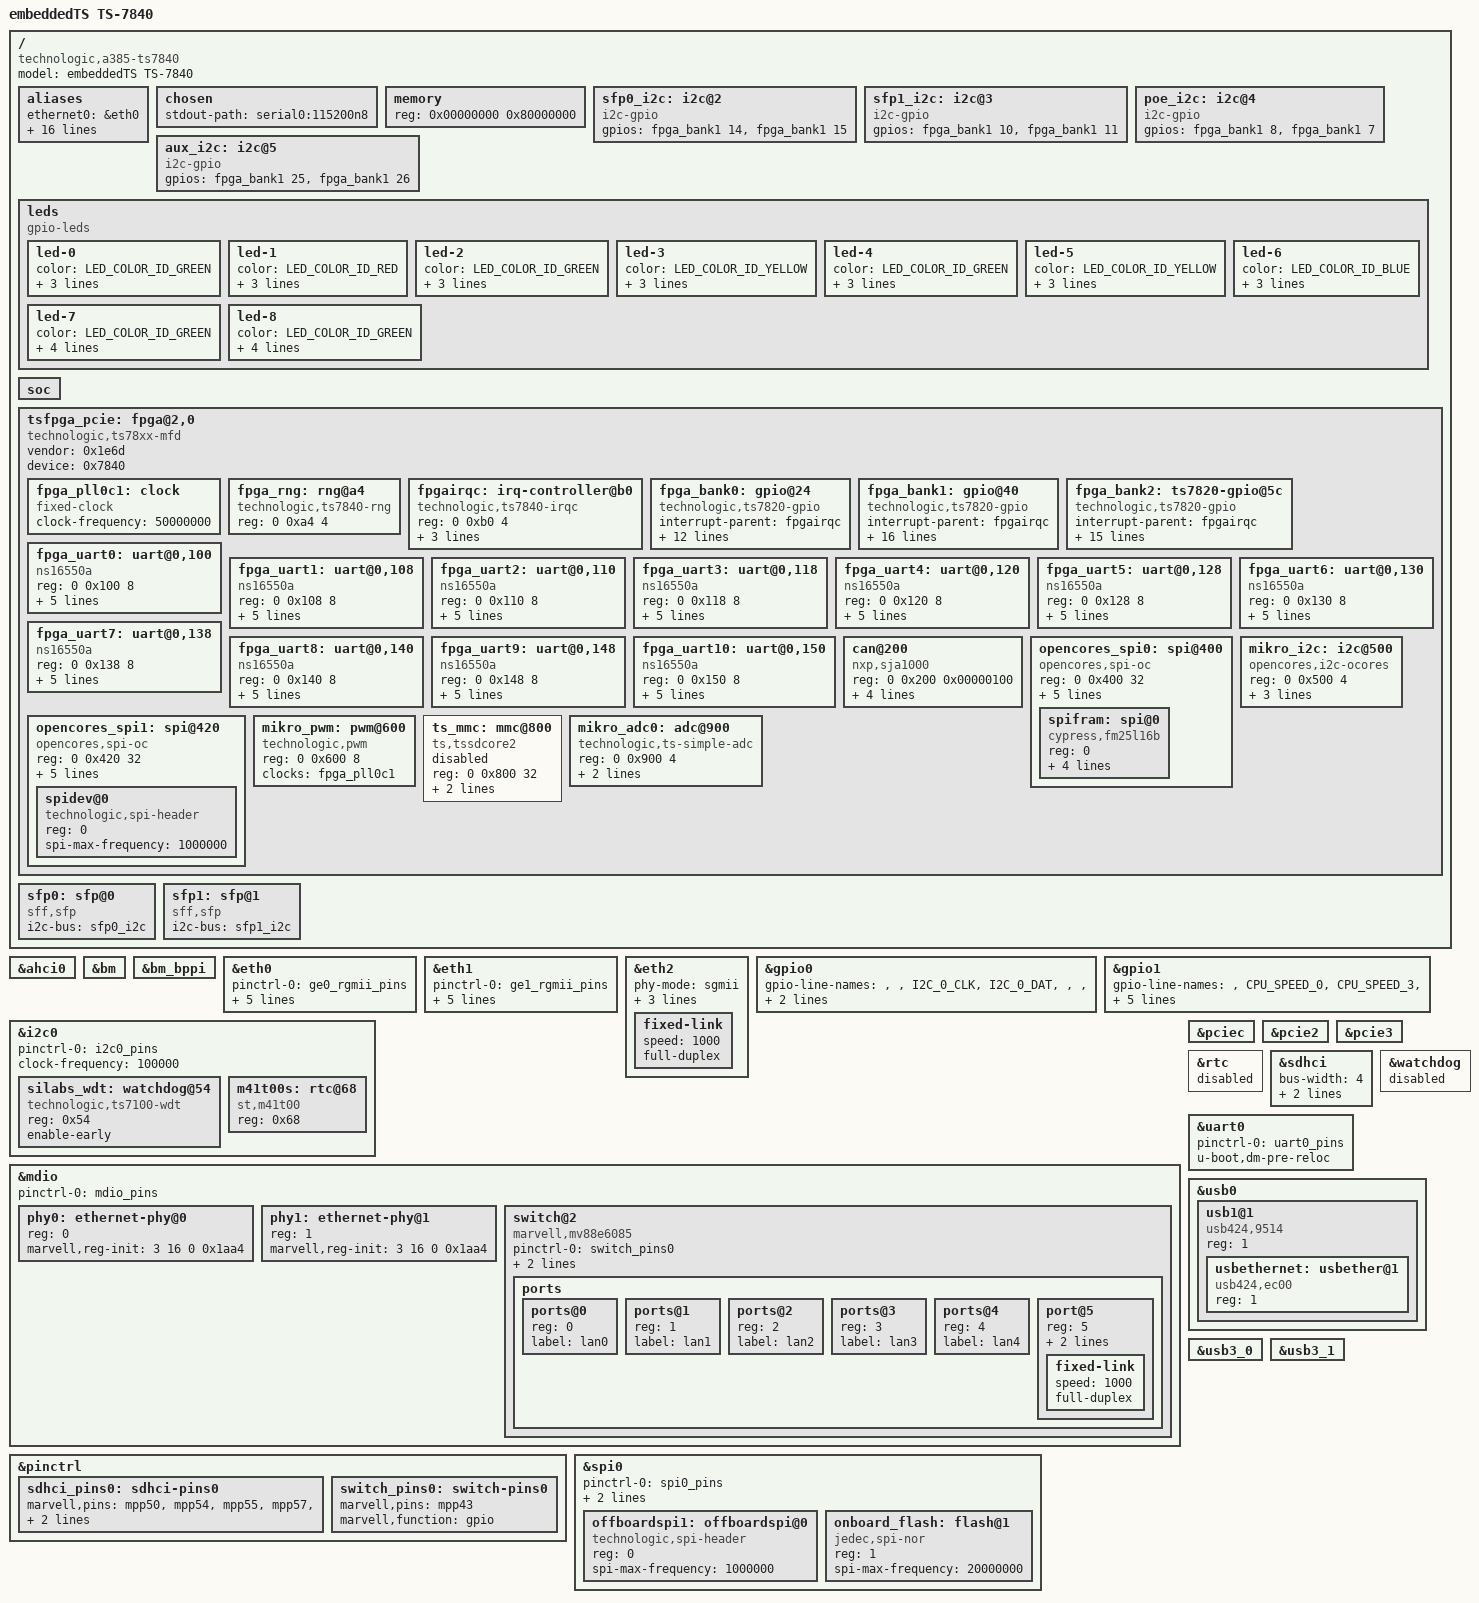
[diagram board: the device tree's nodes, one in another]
// SPDX-License-Identifier: (GPL-2.0+ OR X11)
/*
 * Device Tree file for embeddedTS TS-7840
 * Copyright (C) 2017-2022 Technologic Systems, Inc. dba embeddedTS
 */
/dts-v1/;
#include "armada-385.dtsi"

#include <dt-bindings/gpio/gpio.h>
#include <dt-bindings/leds/common.h>
#include <dt-bindings/interrupt-controller/irq.h>

/ {
	model = "embeddedTS TS-7840";
	compatible = "technologic,a385-ts7840", "marvell,armada385", "marvell,armada380";

	aliases {
		ethernet0 = &eth0;
		ethernet1 = &eth1;
		ethernet2 = &eth2;
		ethernet3 = &usbethernet;

		gpio2 = &fpga_bank0;
		gpio3 = &fpga_bank1;
		gpio4 = &fpga_bank2;

		spi0 = &spi0;
		spi3 = &opencores_spi0;
		spi4 = &opencores_spi1;

		i2c0 = &i2c0;
		i2c1 = &i2c1;
		i2c2 = &sfp0_i2c;
		i2c3 = &sfp1_i2c;
		i2c4 = &poe_i2c;
		i2c5 = &aux_i2c;
		i2c6 = &mikro_i2c;
	};

	chosen {
		stdout-path = "serial0:115200n8";
	};

	memory {
		device_type = "memory";
		reg = <0x00000000 0x80000000>; /* 2GB */
	};

	sfp0_i2c: i2c@2 {
		compatible = "i2c-gpio";
		gpios = <&fpga_bank1 14 (GPIO_ACTIVE_HIGH | GPIO_OPEN_DRAIN)>, /* sda */
			<&fpga_bank1 15 (GPIO_ACTIVE_HIGH | GPIO_OPEN_DRAIN)>; /* scl */
		#address-cells = <1>;
		#size-cells = <0>;
	};

	sfp1_i2c: i2c@3 {
		compatible = "i2c-gpio";
		gpios = <&fpga_bank1 10 (GPIO_ACTIVE_HIGH | GPIO_OPEN_DRAIN)>, /* sda */
			<&fpga_bank1 11 (GPIO_ACTIVE_HIGH | GPIO_OPEN_DRAIN)>; /* scl */
		#address-cells = <1>;
		#size-cells = <0>;
	};

	poe_i2c: i2c@4 {
		compatible = "i2c-gpio";
		gpios = <&fpga_bank1 8 (GPIO_ACTIVE_HIGH | GPIO_OPEN_DRAIN)>, /* sda */
			<&fpga_bank1 7 (GPIO_ACTIVE_HIGH | GPIO_OPEN_DRAIN)>; /* scl */
		#address-cells = <1>;
		#size-cells = <0>;
	};

	aux_i2c: i2c@5 {
		compatible = "i2c-gpio";
		gpios = <&fpga_bank1 25 (GPIO_ACTIVE_HIGH | GPIO_OPEN_DRAIN)>, /* sda */
			<&fpga_bank1 26 (GPIO_ACTIVE_HIGH | GPIO_OPEN_DRAIN)>; /* scl */
		#address-cells = <1>;
		#size-cells = <0>;
	};

	leds {
		compatible = "gpio-leds";

		led-0 {
			color = <LED_COLOR_ID_GREEN>;
			function = LED_FUNCTION_POWER;
			gpios = <&fpga_bank0 19 GPIO_ACTIVE_LOW>;
			default-state = "on";
		};

		led-1 {
			color = <LED_COLOR_ID_RED>;
			function = LED_FUNCTION_STATUS;
			gpios = <&fpga_bank0 20 GPIO_ACTIVE_LOW>;
			default-state = "off";
		};

		led-2 {
			color = <LED_COLOR_ID_GREEN>;
			function = LED_FUNCTION_INDICATOR;
			gpios = <&fpga_bank0 21 GPIO_ACTIVE_LOW>;
			default-state = "off";
		};

		led-3 {
			color = <LED_COLOR_ID_YELLOW>;
			function = LED_FUNCTION_INDICATOR;
			gpios = <&fpga_bank0 22 GPIO_ACTIVE_LOW>;
			default-state = "off";
		};

		led-4 {
			color = <LED_COLOR_ID_GREEN>;
			function = LED_FUNCTION_INDICATOR;
			gpios = <&fpga_bank0 23 GPIO_ACTIVE_LOW>;
			default-state = "off";
		};

		led-5 {
			color = <LED_COLOR_ID_YELLOW>;
			function = LED_FUNCTION_INDICATOR;
			gpios = <&fpga_bank0 24 GPIO_ACTIVE_LOW>;
			default-state = "off";
		};

		led-6 {
			color = <LED_COLOR_ID_BLUE>;
			function = LED_FUNCTION_INDICATOR;
			gpios = <&fpga_bank0 25 GPIO_ACTIVE_HIGH>;
			default-state = "off";
		};

		led-7 {
			color = <LED_COLOR_ID_GREEN>;
			gpios = <&fpga_bank0 26 GPIO_ACTIVE_LOW>;
			function = LED_FUNCTION_INDICATOR;
			linux,default-trigger = "f1072004.mdio-mii:01:1Gbps";
		};

		led-8 {
			color = <LED_COLOR_ID_GREEN>;
			gpios = <&fpga_bank2 20 GPIO_ACTIVE_LOW>;
			function = LED_FUNCTION_INDICATOR;
			linux,default-trigger = "f1072004.mdio-mii:00:1Gbps";
		};
	};

	soc {
		ranges = <MBUS_ID(0xf0, 0x01) 0 0xf1000000 0x100000
			  MBUS_ID(0x01, 0x1d) 0 0xfff00000 0x100000
			  MBUS_ID(0x09, 0x19) 0 0xf1100000 0x10000
			  MBUS_ID(0x09, 0x15) 0 0xf1110000 0x10000
			  MBUS_ID(0x0c, 0x04) 0 0xf1200000 0x100000>;
	};

	tsfpga_pcie: fpga@2,0 {
		compatible = "technologic,ts78xx-mfd";
		#address-cells = <2>;
		#size-cells = <1>;

		vendor = <0x1e6d>;
		device = <0x7840>;

		/* <ranges> is set in the driver at runtime */

		fpga_pll0c1: clock {
			compatible = "fixed-clock";
			#clock-cells = <0>;
			clock-frequency = <50000000>;
		};

		fpga_rng: rng@a4 {
			compatible = "technologic,ts7840-rng";
			reg = <0 0xa4 4>;
		};

		fpgairqc: irq-controller@b0 {
			compatible = "technologic,ts7840-irqc";
			reg = <0 0xb0 4>;
			interrupt-controller;
			#interrupt-cells = <2>;
			interrupt-parent = <&gpio1>;
			interrupts = <3 IRQ_TYPE_LEVEL_HIGH>;
		};

		fpga_bank0: gpio@24 {
			compatible = "technologic,ts7820-gpio";

			interrupt-parent = <&fpgairqc>;
			interrupts = <16 IRQ_TYPE_LEVEL_HIGH>;

			interrupt-controller;
			#interrupt-cells = <2>;

			gpio-controller;
			#gpio-cells = <2>;
			reg = <0 0x24 0x1c>;

			gpio-line-names = "", "", "", "", "", "", "", "", "",
				"", "", "", "", "", "", "", "power_fail_3v_pad",
				"detect_9478_pad", "", "magjack_1_led_padn",
				"blu_led_padn", "right_grn_led_padn",
				"right_red_led_padn", "middle_grn_led_padn",
				"middle_yel_led_padn", "left_grn_led_padn",
				"left_yel_led_padn", "bt_en_pad", "wifi_en_pad",
				"prog_silab_clk_padn", "prog_silab_data_pad",
				"cpu_push_sw_padn";
		};

		fpga_bank1: gpio@40 {
			compatible = "technologic,ts7820-gpio";

			interrupt-parent = <&fpgairqc>;
			interrupts = <17 IRQ_TYPE_LEVEL_HIGH>;

			interrupt-controller;
			#interrupt-cells = <2>;

			gpio-controller;
			#gpio-cells = <2>;
			reg = <0 0x40 0x1c>;

			gpio-line-names = "DIG_IO_1", "DIG_IO_2", "DIG_IO_3",
				"en_hs_sw_pad", "mikro_pwm_pad",
				"dio_fault_3v_padn", "en_poe_padn",
				"i2c_poe_clk_pad", "i2c_poe_dat",
				"spi_0_fpga_cs3_pad", "cage1_sda_pad",
				"cage1_scl_pad", "", "", "cage2_sda_pad",
				"cage2_scl_pad", "en_nimbel_4v_pad",
				"en_nimbel_3v3_pad", "en_emmc_3v3_pad",
				"en_modem_5v_pad", "en_usb_5v_pad",
				"disable_nim_usb_pad", "mini_pcie_reset_padn",
				"ssd_present_padn", "en_xbee_usb_padn",
				"aux_i2c_dat_pad", "aux_i2c_clk_pad", "", "",
				"", "", "";
		};

		fpga_bank2: ts7820-gpio@5c {
			compatible = "technologic,ts7820-gpio";

			interrupt-parent = <&fpgairqc>;
			interrupts = <18 IRQ_TYPE_LEVEL_HIGH>;

			interrupt-controller;
			#interrupt-cells = <2>;

			gpio-controller;
			#gpio-cells = <2>;
			reg = <0 0x5c 0x1c>;

			gpio-line-names = "ird_network_rdy_pad",
				"ird_modem_on_pad", "eth_100_act_padn",
				"eth_100_speed_padn", "ssd_act_padn",
				"mini_sr_latch_pad", "", "", "", "",
				"mikro_int_pad", "mikro_reset_padn",
				"mikro_an_3v_pad", "mikro_i2c_clk_pad",
				"mikro_i2c_dat_pad", "alt_mikro_pwm_pad",
				"mikro_an_pwm_pad", "comp_pad", "mikro_180_pad",
				"en_mini_5v_pad", "magjack_0_led_padn",
				"hd10_2_pad", "hd10_4_pad", "hd10_5_pad",
				"hd10_6_pad", "hd10_8_pad", "jp1_padn",
				"jp2_padn", "", "", "", "";
		};

		/* COM1 RS-232 */
		fpga_uart0: uart@0,100 {
			compatible = "ns16550a";
			reg = <0 0x100 8>;
			interrupt-parent = <&fpgairqc>;
			interrupts = <0 IRQ_TYPE_LEVEL_HIGH>;
			clock-frequency = <1843200>;
			reg-io-width = <1>;
			fifo-size = <64>;
		};

		/* COM2 RS-232 */
		fpga_uart1: uart@0,108 {
			compatible = "ns16550a";
			reg = <0 0x108 8>;
			interrupt-parent = <&fpgairqc>;
			interrupts = <1 IRQ_TYPE_LEVEL_HIGH>;
			clock-frequency = <1843200>;
			reg-io-width = <1>;
			fifo-size = <64>;
		};

		/* GPS */
		fpga_uart2: uart@0,110 {
			compatible = "ns16550a";
			reg = <0 0x110 8>;
			interrupt-parent = <&fpgairqc>;
			interrupts = <2 IRQ_TYPE_LEVEL_HIGH>;
			clock-frequency = <1843200>;
			reg-io-width = <1>;
			fifo-size = <64>;
		};

		/* Nimbelink */
		fpga_uart3: uart@0,118 {
			compatible = "ns16550a";
			reg = <0 0x118 8>;
			interrupt-parent = <&fpgairqc>;
			interrupts = <3 IRQ_TYPE_LEVEL_HIGH>;
			clock-frequency = <1843200>;
			reg-io-width = <1>;
			fifo-size = <64>;
		};

		/* Iridium Modem */
		fpga_uart4: uart@0,120 {
			compatible = "ns16550a";
			reg = <0 0x120 8>;
			interrupt-parent = <&fpgairqc>;
			interrupts = <4 IRQ_TYPE_LEVEL_HIGH>;
			clock-frequency = <1843200>;
			reg-io-width = <1>;
			fifo-size = <64>;
		};

		/* DSL Modem */
		fpga_uart5: uart@0,128 {
			compatible = "ns16550a";
			reg = <0 0x128 8>;
			interrupt-parent = <&fpgairqc>;
			interrupts = <5 IRQ_TYPE_LEVEL_HIGH>;
			clock-frequency = <1843200>;
			reg-io-width = <1>;
			fifo-size = <64>;
		};

		/* Mikrobus UART */
		fpga_uart6: uart@0,130 {
			compatible = "ns16550a";
			reg = <0 0x130 8>;
			interrupt-parent = <&fpgairqc>;
			interrupts = <6 IRQ_TYPE_LEVEL_HIGH>;
			clock-frequency = <1843200>;
			reg-io-width = <1>;
			fifo-size = <64>;
		};

		/* RS-485 port */
		fpga_uart7: uart@0,138 {
			compatible = "ns16550a";
			reg = <0 0x138 8>;
			interrupt-parent = <&fpgairqc>;
			interrupts = <7 IRQ_TYPE_LEVEL_HIGH>;
			clock-frequency = <1843200>;
			reg-io-width = <1>;
			fifo-size = <64>;
		};

		/* XBEE */
		fpga_uart8: uart@0,140 {
			compatible = "ns16550a";
			reg = <0 0x140 8>;
			interrupt-parent = <&fpgairqc>;
			interrupts = <8 IRQ_TYPE_LEVEL_HIGH>;
			clock-frequency = <1843200>;
			reg-io-width = <1>;
			fifo-size = <64>;
		};

		/* Spare */
		fpga_uart9: uart@0,148 {
			compatible = "ns16550a";
			reg = <0 0x148 8>;
			interrupt-parent = <&fpgairqc>;
			interrupts = <19 IRQ_TYPE_LEVEL_HIGH>;
			clock-frequency = <1843200>;
			reg-io-width = <1>;
			fifo-size = <64>;
		};

		/* Spare */
		fpga_uart10: uart@0,150 {
			compatible = "ns16550a";
			reg = <0 0x150 8>;
			interrupt-parent = <&fpgairqc>;
			interrupts = <20 IRQ_TYPE_LEVEL_HIGH>;
			clock-frequency = <1843200>;
			reg-io-width = <1>;
			fifo-size = <64>;
		};

		can@200 {
			compatible = "nxp,sja1000";
			reg = <0 0x200 0x00000100>;
			interrupt-parent = <&fpgairqc>;
			interrupts = <10 IRQ_TYPE_LEVEL_HIGH>;
			reg-io-width = <1>;
			nxp,external-clock-frequency = <16000000>;
		};

		opencores_spi0: spi@400 {
			compatible = "opencores,spi-oc";
			reg = <0 0x400 32>;
			interrupt-parent = <&fpgairqc>;
			interrupts = <11 IRQ_TYPE_LEVEL_HIGH>;
			clocks = <&fpga_pll0c1>;
			clock-names ="spi-oc-clk";
			opencores-spi,idx = <0>;
			opencores-spi,num-chipselects = <1>;

			#address-cells = <1>;
			#size-cells = <0>;

			spifram: spi@0 {
				compatible = "cypress,fm25l16b", "atmel,at25";
				reg = <0>;
				spi-max-frequency = <19800000>;
				size = <0x800>;
				address-width = <16>;
				pagesize = <64>;
			};
		};

		opencores_spi1: spi@420 {
			compatible = "opencores,spi-oc";
			reg = <0 0x420 32>;
			interrupt-parent = <&fpgairqc>;
			interrupts = <12 IRQ_TYPE_LEVEL_HIGH>;
			clocks = <&fpga_pll0c1>;
			clock-names ="spi-oc-clk";
			opencores-spi,idx = <0>;
			opencores-spi,num-chipselects = <1>;

			#address-cells = <1>;
			#size-cells = <0>;

			spidev@0 {
				compatible = "technologic,spi-header";
				reg = <0>;
				spi-max-frequency = <1000000>;
			};
		};

		mikro_i2c: i2c@500 {
			compatible = "opencores,i2c-ocores";
			reg = <0 0x500 4>;
			interrupt-parent = <&fpgairqc>;
			interrupts = <13 IRQ_TYPE_LEVEL_HIGH>;
			clocks = <&fpga_pll0c1>;
			clock-names = "i2c-oc-clk";
		};

		mikro_pwm: pwm@600 {
			compatible = "technologic,pwm";
			reg = <0 0x600 8>;
			clocks = <&fpga_pll0c1>;
			clock-names = "pwm-input-clk";
		};

		ts_mmc: mmc@800 {
			compatible = "ts,tssdcore2";
			reg = <0 0x800 32>;
			//interrupt-parent = <&fpgairqc>;
			//interrupts = <14 IRQ_TYPE_LEVEL_HIGH>;
			busy-gpios = <&fpga_bank0 15 GPIO_ACTIVE_HIGH>;
			debug-gpios = <&fpga_bank1 12 GPIO_ACTIVE_HIGH>;
			status = "disabled";
		};

		mikro_adc0: adc@900 {
			compatible = "technologic,ts-simple-adc";
			reg = <0 0x900 4>;
			interrupt-parent = <&fpgairqc>;
			interrupts = <21 IRQ_TYPE_LEVEL_HIGH>;
		};
	};

	sfp0: sfp@0 {
		compatible = "sff,sfp";
		i2c-bus = <&sfp0_i2c>;
	};

	sfp1: sfp@1 {
		compatible = "sff,sfp";
		i2c-bus = <&sfp1_i2c>;
	};
};

&ahci0 {
	status = "okay";
};

&bm {
	status = "okay";
};

&bm_bppi {
	status = "okay";
};

/* magjack/sfp port 0 */
&eth0 {
	pinctrl-names = "default";
	pinctrl-0 = <&ge0_rgmii_pins>;
	status = "okay";
	phy = <&phy0>;
	phy-mode = "rgmii-id";
	buffer-manager = <&bm>;
	/*sfp = <&sfp0>;*/
	bm,pool-long = <0>;
	bm,pool-short = <1>;
};

/* magjack/sfgp port 1 */
&eth1 {
	pinctrl-names = "default";
	pinctrl-0 = <&ge1_rgmii_pins>;
	status = "okay";
	phy = <&phy1>;
	phy-mode = "rgmii-id";
	/*sfp = <&sfp1>;*/
	bm,pool-long = <2>;
	bm,pool-short = <1>;
	buffer-manager = <&bm>;
};

/* sgmii port to eth switch */
&eth2 {
	status = "okay";
	phy-mode = "sgmii";
	bm,pool-long = <3>;
	bm,pool-short = <1>;
	buffer-manager = <&bm>;

	fixed-link {
		speed = <1000>;
		full-duplex;
	};
};

&gpio0 {
	gpio-line-names = "", "", "I2C_0_CLK", "I2C_0_DAT", "", "", "", "", "",
		"", "", "", "", "", "", "", "", "", "WIFI_IRQ_N", "FPGA_RESET",
		"", "", "", "", "", "", "", "", "", "", "", "";
};

&gpio1 {
	gpio-line-names = "", "CPU_SPEED_0", "CPU_SPEED_3", "CPU_SPEED_4",
		"CPU_TYPE_0", "", "", "", "", "", "GPS_PPS", "ETH_SW_INT#",
		"CPU_TYPE_1", "", "", "", "", "FPGA_FLASH_SELECT", "EMMC_CMD",
		"SPREAD_SPECTRUM#", "", "DETECT_9478", "", "", "", "", "", "",
		"", "", "", "";
};

&i2c0 {
	pinctrl-names = "default";
	pinctrl-0 = <&i2c0_pins>;
	clock-frequency = <100000>;
	status = "okay";

	silabs_wdt: watchdog@54 {
		compatible = "technologic,ts7100-wdt";
		reg = <0x54>;
		enable-early;
	};

	m41t00s: rtc@68 {
		compatible = "st,m41t00";
		reg = <0x68>;
	};
};

&mdio {
	pinctrl-names = "default";
	pinctrl-0 = <&mdio_pins>;

	phy0: ethernet-phy@0 {
		reg = <0>;
		/* Configure LED[0] to blink for activity */
		marvell,reg-init = <3 16 0 0x1aa4>;
	};

	phy1: ethernet-phy@1 {
		reg = <1>;
		/* Configure LED[0] to blink for activity */
		marvell,reg-init = <3 16 0 0x1aa4>;
	};

	switch@2 {
		compatible = "marvell,mv88e6085";

		pinctrl-names = "default";
		pinctrl-0 = <&switch_pins0>;

		#address-cells = <1>;
		#size-cells = <0>;
		dsa,member = <0 0>;
		reg = <2>;

		ports {
			#address-cells = <1>;
			#size-cells = <0>;

			ports@0 {
				reg = <0>;
				label = "lan0";
			};

			ports@1 {
				reg = <1>;
				label = "lan1";
			};

			ports@2 {
				reg = <2>;
				label = "lan2";
			};

			ports@3 {
				reg = <3>;
				label = "lan3";
			};

			ports@4 {
				reg = <4>;
				label = "lan4";
			};

			port@5 {
				reg = <5>;
				label = "cpu";
				ethernet = <&eth2>;
				fixed-link {
					speed = <1000>;
					full-duplex;
				};
			};
		};
	};
};

&pciec {
	status = "okay";
};

/* Mini PCIe */
&pcie2 {
	status = "okay";
};

/* FPGA */
&pcie3 {
	status = "okay";
};

&pinctrl {
	sdhci_pins0: sdhci-pins0 {
		marvell,pins = "mpp50", "mpp54", "mpp55",
			       "mpp57", "mpp58", "mpp59";
		marvell,function = "sd0";
	};

	switch_pins0: switch-pins0 {
		marvell,pins = "mpp43";
		marvell,function = "gpio";
	};
};

/* We do not use the CPU's built in RTC */
&rtc {
	status = "disabled";
};

&sdhci {
	bus-width = <4>;
	no-1-8-v;
	pinctrl-0 = <&sdhci_pins0>;
	pinctrl-names = "default";
	status = "okay";
};

&spi0 {
	pinctrl-names = "default";
	pinctrl-0 = <&spi0_pins>;
	status = "okay";
	num-cs = <3>;
	cs-gpios = <0>, <&fpga_bank1 9 GPIO_ACTIVE_LOW>;

	offboardspi1: offboardspi@0 {
		compatible = "technologic,spi-header";
		reg = <0>;
		spi-max-frequency = <1000000>;
	};

	onboard_flash: flash@1 {
		compatible = "jedec,spi-nor";
		reg = <1>;
		spi-max-frequency = <20000000>;
	};
};

&uart0 {
	pinctrl-0 = <&uart0_pins>;
	pinctrl-names = "default";
	status = "okay";
	u-boot,dm-pre-reloc;
};

/* We use an external watchdog */
&watchdog {
	status = "disabled";
};

&usb0 {
	#address-cells = <1>;
	#size-cells = <0>;
	status = "okay";

	usb1@1 {
		compatible = "usb424,9514";
		reg = <1>;
		#address-cells = <1>;
		#size-cells = <0>;

		usbethernet: usbether@1 {
			compatible = "usb424,ec00";
			reg = <1>;
		};
	};
};

&usb3_0 {
	status = "okay";
};

&usb3_1 {
	status = "okay";
};
